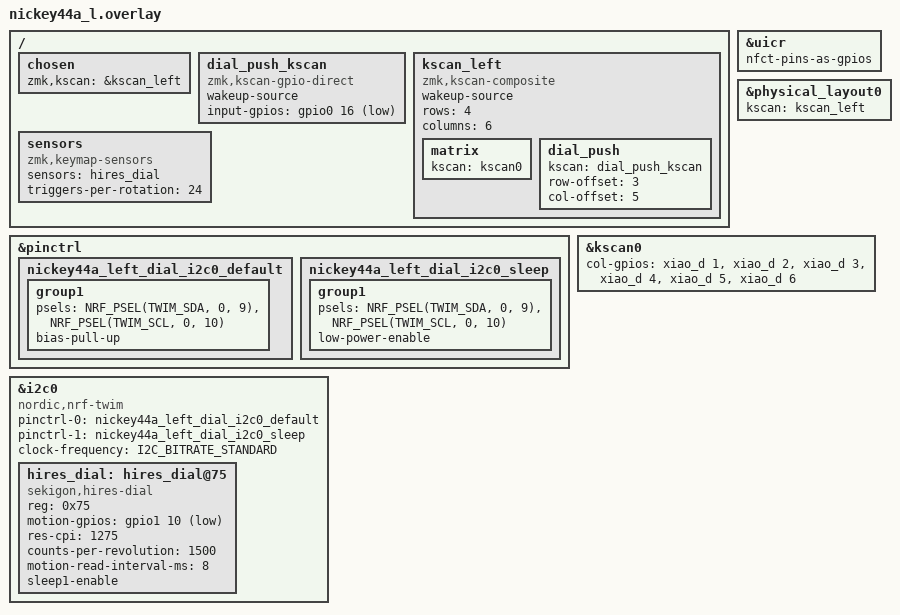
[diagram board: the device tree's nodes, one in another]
#include "nickey44a.dtsi"
#include <dt-bindings/pinctrl/nrf-pinctrl.h>

/*
 * Left half: sekigon hires-dial-module (PAT9125) instead of the TPS43 pad.
 * Wiring via the pitch-conversion FPC (pad 6 = square pad):
 *   FPC 1 GND    -> board pad 1 (GND)
 *   FPC 2 SDA    -> board pad 2 = XIAO NFC1/P0.09
 *   FPC 3 SCL    -> board pad 3 = XIAO NFC2/P0.10
 *   FPC 4 PUSH   -> XIAO P0.16 (white wire, low while pressed)
 *   FPC 5 MOTION -> XIAO P1.10 (yellow wire, active low)
 *   FPC 6 3.3V   -> board pad 6 (3.3V)
 */

&uicr {
    nfct-pins-as-gpios;
};

&pinctrl {
    nickey44a_left_dial_i2c0_default: nickey44a_left_dial_i2c0_default {
        group1 {
            psels = <NRF_PSEL(TWIM_SDA, 0, 9)>,
                    <NRF_PSEL(TWIM_SCL, 0, 10)>;
            /* The dial module has no I2C pull-up resistors. */
            bias-pull-up;
        };
    };

    nickey44a_left_dial_i2c0_sleep: nickey44a_left_dial_i2c0_sleep {
        group1 {
            psels = <NRF_PSEL(TWIM_SDA, 0, 9)>,
                    <NRF_PSEL(TWIM_SCL, 0, 10)>;
            low-power-enable;
        };
    };
};

/ {
    chosen {
        zmk,kscan = &kscan_left;
    };

    /* Dial push = matrix position RC(3,5), the left inner key that the pad /
     * dial replaces (keymap index 30). */
    dial_push_kscan: dial_push_kscan {
        compatible = "zmk,kscan-gpio-direct";
        wakeup-source;
        input-gpios = <&gpio0 16 (GPIO_ACTIVE_LOW | GPIO_PULL_UP)>;
    };

    kscan_left: kscan_left {
        compatible = "zmk,kscan-composite";
        wakeup-source;
        rows = <4>;
        columns = <6>;

        matrix {
            kscan = <&kscan0>;
        };

        dial_push {
            kscan = <&dial_push_kscan>;
            row-offset = <3>;
            col-offset = <5>;
        };
    };

    sensors: sensors {
        compatible = "zmk,keymap-sensors";
        sensors = <&hires_dial>;
        /* Must match the right overlay (sensor indices are shared). */
        triggers-per-rotation = <24>;
    };
};

&physical_layout0 {
    kscan = <&kscan_left>;
};

&i2c0 {
    status = "okay";
    compatible = "nordic,nrf-twim";
    pinctrl-0 = <&nickey44a_left_dial_i2c0_default>;
    pinctrl-1 = <&nickey44a_left_dial_i2c0_sleep>;
    pinctrl-names = "default", "sleep";
    clock-frequency = <I2C_BITRATE_STANDARD>;
    #address-cells = <1>;
    #size-cells = <0>;

    hires_dial: hires_dial@75 {
        compatible = "sekigon,hires-dial";
        reg = <0x75>;
        motion-gpios = <&gpio1 10 (GPIO_ACTIVE_LOW | GPIO_PULL_UP)>;
        res-cpi = <1275>;
        /* About 1500 counts per turn (module README). Keep equal to the
         * remote node in the right overlay. */
        counts-per-revolution = <1500>;
        motion-read-interval-ms = <8>;
        /* If turning clockwise lowers the volume, uncomment this. */
        /* invert; */
        sleep1-enable;
    };
};

&kscan0 {
        col-gpios
            = <&xiao_d 1 GPIO_ACTIVE_HIGH>
            , <&xiao_d 2 GPIO_ACTIVE_HIGH>
            , <&xiao_d 3 GPIO_ACTIVE_HIGH>
            , <&xiao_d 4 GPIO_ACTIVE_HIGH>
            , <&xiao_d 5 GPIO_ACTIVE_HIGH>
            , <&xiao_d 6 GPIO_ACTIVE_HIGH>
            ;
};
